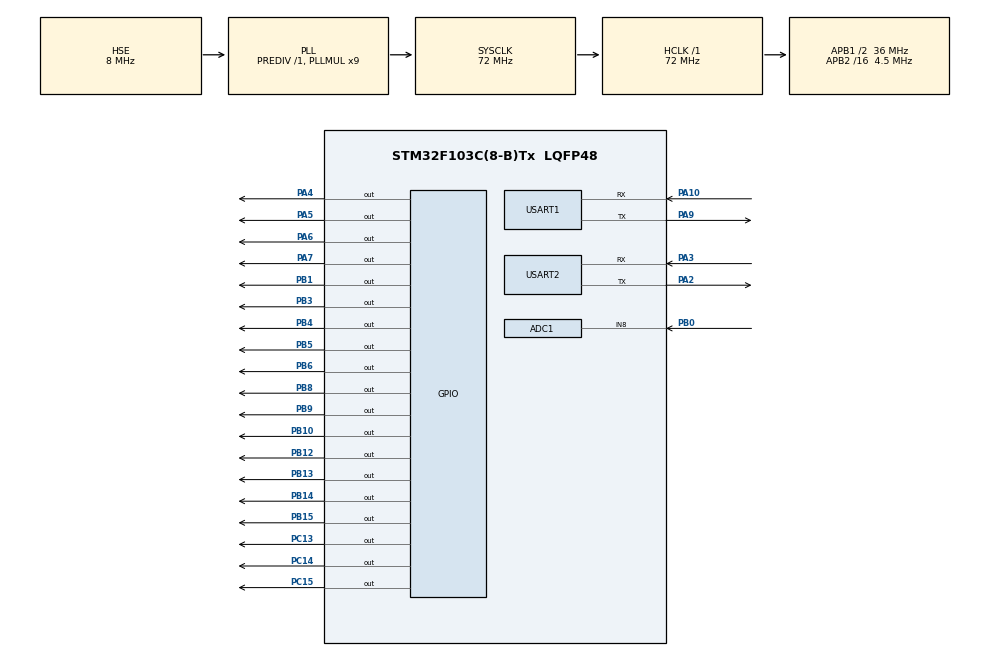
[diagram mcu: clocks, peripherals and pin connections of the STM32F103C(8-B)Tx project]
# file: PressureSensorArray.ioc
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ADC1.Channel-1\#ChannelRegularConversion=ADC_CHANNEL_8
ADC1.ContinuousConvMode=ENABLE
ADC1.EnableAnalogWatchDog=false
ADC1.EnableInjectedConversion=DISABLE
ADC1.InjNumberOfConversion=1
ADC1.NbrOfConversionFlag=1
ADC1.Rank-1\#ChannelRegularConversion=1
ADC1.SamplingTime-1\#ChannelRegularConversion=ADC_SAMPLETIME_239CYCLES_5
ADC1.master=1
Dma.Request0=USART1_TX
Dma.Request1=USART1_RX
Dma.Request2=USART2_RX
Dma.Request3=USART2_TX
Dma.USART1_RX.1.Direction=DMA_PERIPH_TO_MEMORY
Dma.USART1_RX.1.Instance=DMA1_Channel5
Dma.USART1_RX.1.MemDataAlignment=DMA_MDATAALIGN_BYTE
Dma.USART1_RX.1.MemInc=DMA_MINC_ENABLE
Dma.USART1_RX.1.Mode=DMA_NORMAL
Dma.USART1_RX.1.PeriphDataAlignment=DMA_PDATAALIGN_BYTE
Dma.USART1_RX.1.PeriphInc=DMA_PINC_DISABLE
Dma.USART1_RX.1.Priority=DMA_PRIORITY_MEDIUM
Dma.USART1_TX.0.Direction=DMA_MEMORY_TO_PERIPH
Dma.USART1_TX.0.Instance=DMA1_Channel4
Dma.USART1_TX.0.MemDataAlignment=DMA_MDATAALIGN_BYTE
Dma.USART1_TX.0.MemInc=DMA_MINC_ENABLE
Dma.USART1_TX.0.Mode=DMA_NORMAL
Dma.USART1_TX.0.PeriphDataAlignment=DMA_PDATAALIGN_BYTE
Dma.USART1_TX.0.PeriphInc=DMA_PINC_DISABLE
Dma.USART1_TX.0.Priority=DMA_PRIORITY_MEDIUM
Dma.USART2_RX.2.Direction=DMA_PERIPH_TO_MEMORY
Dma.USART2_RX.2.Instance=DMA1_Channel6
Dma.USART2_RX.2.MemDataAlignment=DMA_MDATAALIGN_BYTE
Dma.USART2_RX.2.MemInc=DMA_MINC_ENABLE
Dma.USART2_RX.2.Mode=DMA_NORMAL
Dma.USART2_RX.2.PeriphDataAlignment=DMA_PDATAALIGN_BYTE
Dma.USART2_RX.2.PeriphInc=DMA_PINC_DISABLE
Dma.USART2_RX.2.Priority=DMA_PRIORITY_HIGH
Dma.USART2_TX.3.Direction=DMA_MEMORY_TO_PERIPH
Dma.USART2_TX.3.Instance=DMA1_Channel7
Dma.USART2_TX.3.MemDataAlignment=DMA_MDATAALIGN_BYTE
Dma.USART2_TX.3.MemInc=DMA_MINC_ENABLE
Dma.USART2_TX.3.Mode=DMA_NORMAL
Dma.USART2_TX.3.PeriphDataAlignment=DMA_PDATAALIGN_BYTE
Dma.USART2_TX.3.PeriphInc=DMA_PINC_DISABLE
Dma.USART2_TX.3.Priority=DMA_PRIORITY_HIGH
Mcu.Family=STM32F1
Mcu.Name=STM32F103C(8-B)Tx
Mcu.Package=LQFP48
NVIC.ADC1_2_IRQn=true\:0\:0\:false\:false\:true\:true\:true\:true
NVIC.DMA1_Channel4_IRQn=true\:0\:0\:false\:false\:true\:false\:true\:true
NVIC.DMA1_Channel5_IRQn=true\:0\:0\:false\:false\:true\:false\:true\:true
NVIC.DMA1_Channel6_IRQn=true\:0\:0\:false\:false\:true\:false\:true\:true
NVIC.DMA1_Channel7_IRQn=true\:0\:0\:false\:false\:true\:false\:true\:true
NVIC.PriorityGroup=NVIC_PRIORITYGROUP_4
NVIC.USART1_IRQn=true\:0\:0\:false\:false\:true\:true\:true\:true
NVIC.USART2_IRQn=true\:0\:0\:false\:false\:true\:true\:true\:true
PA10.Mode=Asynchronous
PA10.Signal=USART1_RX
PA13.Mode=Serial_Wire
PA13.Signal=SYS_JTMS-SWDIO
PA14.Mode=Serial_Wire
PA14.Signal=SYS_JTCK-SWCLK
PA2.Mode=Asynchronous
PA2.Signal=USART2_TX
PA3.Mode=Asynchronous
PA3.Signal=USART2_RX
PA4.Signal=GPIO_Output
PA5.Signal=GPIO_Output
PA6.Signal=GPIO_Output
PA7.Signal=GPIO_Output
PA9.Mode=Asynchronous
PA9.Signal=USART1_TX
PB0.Signal=ADCx_IN8
PB1.Signal=GPIO_Output
PB10.Signal=GPIO_Output
PB12.Signal=GPIO_Output
PB13.Signal=GPIO_Output
PB14.Signal=GPIO_Output
PB15.Signal=GPIO_Output
PB3.Signal=GPIO_Output
PB4.Signal=GPIO_Output
PB5.Signal=GPIO_Output
PB6.Signal=GPIO_Output
PB8.Signal=GPIO_Output
PB9.Signal=GPIO_Output
PC13-TAMPER-RTC.Signal=GPIO_Output
PC14-OSC32_IN.Signal=GPIO_Output
PC15-OSC32_OUT.Signal=GPIO_Output
PD0-OSC_IN.Mode=HSE-External-Oscillator
PD0-OSC_IN.Signal=RCC_OSC_IN
PD1-OSC_OUT.Mode=HSE-External-Oscillator
PD1-OSC_OUT.Signal=RCC_OSC_OUT
ProjectManager.HeapSize=0x200
ProjectManager.StackSize=0x400
ProjectManager.TargetToolchain=STM32CubeIDE
RCC.ADCPresc=RCC_ADCPCLK2_DIV8
RCC.AHBFreq_Value=72000000
RCC.APB1CLKDivider=RCC_HCLK_DIV2
RCC.APB1Freq_Value=36000000
RCC.APB1TimFreq_Value=72000000
RCC.APB2CLKDivider=RCC_HCLK_DIV16
RCC.APB2Freq_Value=4500000
RCC.APB2TimFreq_Value=9000000
RCC.HCLKFreq_Value=72000000
RCC.PLLMUL=RCC_PLL_MUL9
RCC.PLLSourceVirtual=RCC_PLLSOURCE_HSE
RCC.SYSCLKFreq_VALUE=72000000
RCC.SYSCLKSource=RCC_SYSCLKSOURCE_PLLCLK
RCC.USBFreq_Value=72000000
SH.ADCx_IN8.0=ADC1_IN8,IN8
USART1.VirtualMode=VM_ASYNC
USART2.VirtualMode=VM_ASYNC
board=custom

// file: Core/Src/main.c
/* USER CODE BEGIN Header */
/**
  ******************************************************************************
  * @file           : main.c
  * @brief          : Main program body
  ******************************************************************************
  * @attention
  *
  * Copyright (c) 2024 STMicroelectronics.
  * All rights reserved.
  *
  * This software is licensed under terms that can be found in the LICENSE file
  * in the root directory of this software component.
  * If no LICENSE file comes with this software, it is provided AS-IS.
  *
  ******************************************************************************
  */
/* USER CODE END Header */
#include "main.h"

/* USER CODE BEGIN Includes */
#include <stdio.h>
/* USER CODE END Includes */

ADC_HandleTypeDef hadc1;

UART_HandleTypeDef huart1;
UART_HandleTypeDef huart2;
DMA_HandleTypeDef hdma_usart1_tx;
DMA_HandleTypeDef hdma_usart1_rx;
DMA_HandleTypeDef hdma_usart2_rx;
DMA_HandleTypeDef hdma_usart2_tx;

/* USER CODE BEGIN PV */
AdcStm32 adc_stm32;
AdcSwitchGpio adc_channel;
AdcSwitchGpio row_channel;
/* USER CODE END PV */

void SystemClock_Config(void);
static void MX_GPIO_Init(void);
static void MX_DMA_Init(void);
static void MX_USART1_UART_Init(void);
static void MX_ADC1_Init(void);
static void MX_USART2_UART_Init(void);

/* USER CODE BEGIN 0 */
#if defined(__GNUC__)
/**
 * @brief Overload printf implement.
 */
int _write(int fd, char *ptr, int len) {
  HAL_UART_Transmit_DMA(&huart1, (uint8_t *)ptr, len);
  return len;
}
#endif
/* USER CODE END 0 */

int main(void)
{

  /* MCU Configuration--------------------------------------------------------*/

  /* Reset of all peripherals, Initializes the Flash interface and the Systick. */
  HAL_Init();

  /* Configure the system clock */
  SystemClock_Config();

  /* Initialize all configured peripherals */
  MX_GPIO_Init();
  MX_DMA_Init();
  MX_USART1_UART_Init();
  MX_ADC1_Init();
  MX_USART2_UART_Init();
  /* USER CODE BEGIN 2 */
  AdcSwitchGpioInit(&adc_channel,ADCSWITCHNUMBER);
  AdcSwitchGpioInit(&row_channel,ROWSWITCHNUMBER);
  AdcInitUser(&adc_stm32);
  Esp8266Init();
  //Esp8266SetUdp();
  /* USER CODE END 2 */

  /* Infinite loop */
  /* USER CODE BEGIN WHILE */

  while (1)
  {
//     HAL_GPIO_WritePin(GPIOC,GPIO_PIN_13,GPIO_PIN_RESET);
//     HAL_Delay(500);
//     HAL_GPIO_WritePin(GPIOC,GPIO_PIN_13,GPIO_PIN_SET);
//     HAL_Delay(500);
     AdcSpinOnce(&adc_stm32);
     //HAL_Delay(1);
    /* USER CODE END WHILE */

  }
}

void SystemClock_Config(void)
{
  RCC_OscInitTypeDef RCC_OscInitStruct = {0};
  RCC_ClkInitTypeDef RCC_ClkInitStruct = {0};
  RCC_PeriphCLKInitTypeDef PeriphClkInit = {0};

  /** Initializes the RCC Oscillators according to the specified parameters
  * in the RCC_OscInitTypeDef structure.
  */
  RCC_OscInitStruct.OscillatorType = RCC_OSCILLATORTYPE_HSE;
  RCC_OscInitStruct.HSEState = RCC_HSE_ON;
  RCC_OscInitStruct.HSEPredivValue = RCC_HSE_PREDIV_DIV1;
  RCC_OscInitStruct.HSIState = RCC_HSI_ON;
  RCC_OscInitStruct.PLL.PLLState = RCC_PLL_ON;
  RCC_OscInitStruct.PLL.PLLSource = RCC_PLLSOURCE_HSE;
  RCC_OscInitStruct.PLL.PLLMUL = RCC_PLL_MUL9;
  if (HAL_RCC_OscConfig(&RCC_OscInitStruct) != HAL_OK)
  {
    Error_Handler();
  }

  /** Initializes the CPU, AHB and APB buses clocks
  */
  RCC_ClkInitStruct.ClockType = RCC_CLOCKTYPE_HCLK|RCC_CLOCKTYPE_SYSCLK
                              |RCC_CLOCKTYPE_PCLK1|RCC_CLOCKTYPE_PCLK2;
  RCC_ClkInitStruct.SYSCLKSource = RCC_SYSCLKSOURCE_PLLCLK;
  RCC_ClkInitStruct.AHBCLKDivider = RCC_SYSCLK_DIV1;
  RCC_ClkInitStruct.APB1CLKDivider = RCC_HCLK_DIV2;
  RCC_ClkInitStruct.APB2CLKDivider = RCC_HCLK_DIV16;

  if (HAL_RCC_ClockConfig(&RCC_ClkInitStruct, FLASH_LATENCY_2) != HAL_OK)
  {
    Error_Handler();
  }
  PeriphClkInit.PeriphClockSelection = RCC_PERIPHCLK_ADC;
  PeriphClkInit.AdcClockSelection = RCC_ADCPCLK2_DIV8;
  if (HAL_RCCEx_PeriphCLKConfig(&PeriphClkInit) != HAL_OK)
  {
    Error_Handler();
  }
}

static void MX_ADC1_Init(void)
{

  ADC_ChannelConfTypeDef sConfig = {0};

  /** Common config
  */
  hadc1.Instance = ADC1;
  hadc1.Init.ScanConvMode = ADC_SCAN_DISABLE;
  hadc1.Init.ContinuousConvMode = ENABLE;
  hadc1.Init.DiscontinuousConvMode = DISABLE;
  hadc1.Init.ExternalTrigConv = ADC_SOFTWARE_START;
  hadc1.Init.DataAlign = ADC_DATAALIGN_RIGHT;
  hadc1.Init.NbrOfConversion = 1;
  if (HAL_ADC_Init(&hadc1) != HAL_OK)
  {
    Error_Handler();
  }

  /** Configure Regular Channel
  */
  sConfig.Channel = ADC_CHANNEL_8;
  sConfig.Rank = ADC_REGULAR_RANK_1;
  sConfig.SamplingTime = ADC_SAMPLETIME_239CYCLES_5;
  if (HAL_ADC_ConfigChannel(&hadc1, &sConfig) != HAL_OK)
  {
    Error_Handler();
  }

}

static void MX_USART1_UART_Init(void)
{

  huart1.Instance = USART1;
  huart1.Init.BaudRate = 115200;
  huart1.Init.WordLength = UART_WORDLENGTH_8B;
  huart1.Init.StopBits = UART_STOPBITS_1;
  huart1.Init.Parity = UART_PARITY_NONE;
  huart1.Init.Mode = UART_MODE_TX_RX;
  huart1.Init.HwFlowCtl = UART_HWCONTROL_NONE;
  huart1.Init.OverSampling = UART_OVERSAMPLING_16;
  if (HAL_UART_Init(&huart1) != HAL_OK)
  {
    Error_Handler();
  }

}

static void MX_USART2_UART_Init(void)
{

  huart2.Instance = USART2;
  huart2.Init.BaudRate = 115200;
  huart2.Init.WordLength = UART_WORDLENGTH_8B;
  huart2.Init.StopBits = UART_STOPBITS_1;
  huart2.Init.Parity = UART_PARITY_NONE;
  huart2.Init.Mode = UART_MODE_TX_RX;
  huart2.Init.HwFlowCtl = UART_HWCONTROL_NONE;
  huart2.Init.OverSampling = UART_OVERSAMPLING_16;
  if (HAL_UART_Init(&huart2) != HAL_OK)
  {
    Error_Handler();
  }

}

static void MX_DMA_Init(void)
{

  /* DMA controller clock enable */
  __HAL_RCC_DMA1_CLK_ENABLE();

  /* DMA interrupt init */
  /* DMA1_Channel4_IRQn interrupt configuration */
  HAL_NVIC_SetPriority(DMA1_Channel4_IRQn, 0, 0);
  HAL_NVIC_EnableIRQ(DMA1_Channel4_IRQn);
  /* DMA1_Channel5_IRQn interrupt configuration */
  HAL_NVIC_SetPriority(DMA1_Channel5_IRQn, 0, 0);
  HAL_NVIC_EnableIRQ(DMA1_Channel5_IRQn);
  /* DMA1_Channel6_IRQn interrupt configuration */
  HAL_NVIC_SetPriority(DMA1_Channel6_IRQn, 0, 0);
  HAL_NVIC_EnableIRQ(DMA1_Channel6_IRQn);
  /* DMA1_Channel7_IRQn interrupt configuration */
  HAL_NVIC_SetPriority(DMA1_Channel7_IRQn, 0, 0);
  HAL_NVIC_EnableIRQ(DMA1_Channel7_IRQn);

}

static void MX_GPIO_Init(void)
{
  GPIO_InitTypeDef GPIO_InitStruct = {0};

  /* GPIO Ports Clock Enable */
  __HAL_RCC_GPIOC_CLK_ENABLE();
  __HAL_RCC_GPIOD_CLK_ENABLE();
  __HAL_RCC_GPIOA_CLK_ENABLE();
  __HAL_RCC_GPIOB_CLK_ENABLE();

  /*Configure GPIO pin Output Level */
  HAL_GPIO_WritePin(GPIOC, GPIO_PIN_13|GPIO_PIN_14|GPIO_PIN_15, GPIO_PIN_RESET);

  /*Configure GPIO pin Output Level */
  HAL_GPIO_WritePin(GPIOA, GPIO_PIN_4|GPIO_PIN_5|GPIO_PIN_6|GPIO_PIN_7, GPIO_PIN_RESET);

  /*Configure GPIO pin Output Level */
  HAL_GPIO_WritePin(GPIOB, GPIO_PIN_1|GPIO_PIN_10|GPIO_PIN_12|GPIO_PIN_13
                          |GPIO_PIN_14|GPIO_PIN_15|GPIO_PIN_3|GPIO_PIN_4
                          |GPIO_PIN_5|GPIO_PIN_6|GPIO_PIN_8|GPIO_PIN_9, GPIO_PIN_RESET);

  /*Configure GPIO pins : PC13 PC14 PC15 */
  GPIO_InitStruct.Pin = GPIO_PIN_13|GPIO_PIN_14|GPIO_PIN_15;
  GPIO_InitStruct.Mode = GPIO_MODE_OUTPUT_PP;
  GPIO_InitStruct.Pull = GPIO_NOPULL;
  GPIO_InitStruct.Speed = GPIO_SPEED_FREQ_LOW;
  HAL_GPIO_Init(GPIOC, &GPIO_InitStruct);

  /*Configure GPIO pins : PA4 PA5 PA6 PA7 */
  GPIO_InitStruct.Pin = GPIO_PIN_4|GPIO_PIN_5|GPIO_PIN_6|GPIO_PIN_7;
  GPIO_InitStruct.Mode = GPIO_MODE_OUTPUT_PP;
  GPIO_InitStruct.Pull = GPIO_NOPULL;
  GPIO_InitStruct.Speed = GPIO_SPEED_FREQ_LOW;
  HAL_GPIO_Init(GPIOA, &GPIO_InitStruct);

  /*Configure GPIO pins : PB1 PB10 PB12 PB13
                           PB14 PB15 PB3 PB4
                           PB5 PB6 PB8 PB9 */
  GPIO_InitStruct.Pin = GPIO_PIN_1|GPIO_PIN_10|GPIO_PIN_12|GPIO_PIN_13
                          |GPIO_PIN_14|GPIO_PIN_15|GPIO_PIN_3|GPIO_PIN_4
                          |GPIO_PIN_5|GPIO_PIN_6|GPIO_PIN_8|GPIO_PIN_9;
  GPIO_InitStruct.Mode = GPIO_MODE_OUTPUT_PP;
  GPIO_InitStruct.Pull = GPIO_NOPULL;
  GPIO_InitStruct.Speed = GPIO_SPEED_FREQ_LOW;
  HAL_GPIO_Init(GPIOB, &GPIO_InitStruct);

}

void Error_Handler(void)
{
  __disable_irq();
  while (1)
  {
  }
}
